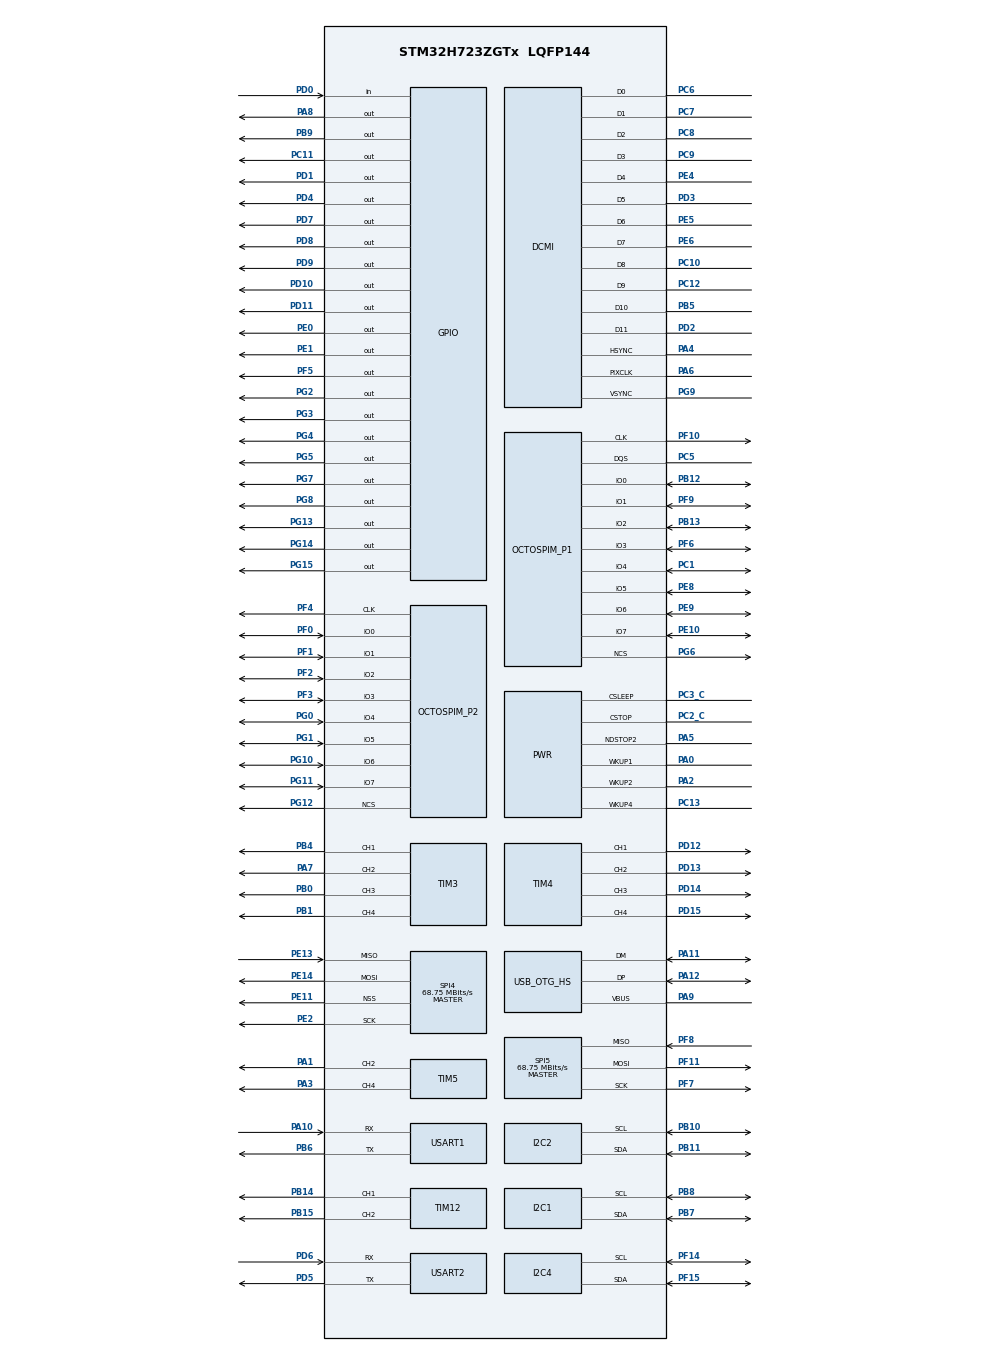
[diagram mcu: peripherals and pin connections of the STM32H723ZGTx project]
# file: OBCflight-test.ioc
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I2C1.Timing=0x60404E72
I2C2.Timing=0x60404E72
I2C4.Timing=0x60404E72
Mcu.Family=STM32H7
Mcu.Name=STM32H723ZGTx
Mcu.Package=LQFP144
NVIC.OTG_HS_IRQn=true\:0\:0\:false\:false\:true\:false\:true\:true
NVIC.PriorityGroup=NVIC_PRIORITYGROUP_4
NVIC.TIM2_IRQn=true\:15\:0\:false\:false\:true\:false\:true\:true
NVIC.TimeBase=TIM2_IRQn
NVIC.TimeBaseIP=TIM2
OCTOSPI1.ChipSelectBoundary=10
OCTOSPI1.ClockPrescaler=4
OCTOSPI1.DelayBlockBypass=HAL_OSPI_DELAY_BLOCK_USED
OCTOSPI1.DelayHoldQuarterCycle=HAL_OSPI_DHQC_ENABLE
OCTOSPI1.DeviceSize=28
OCTOSPI1.DeviceType=SPI_DEVICE_RAM
OCTOSPI1.MemoryType=HAL_OSPI_MEMTYPE_APMEMORY
OCTOSPI1.Refresh=241
OCTOSPI2.ClockPrescaler=4
PA0.Mode=WakeUp1
PA0.Signal=PWR_WKUP1
PA1.Signal=S_TIM5_CH2
PA10.Mode=Asynchronous
PA10.Signal=USART1_RX
PA11.Mode=Device_Only_FS
PA11.Signal=USB_OTG_HS_DM
PA12.Mode=Device_Only_FS
PA12.Signal=USB_OTG_HS_DP
PA13(JTMS/SWDIO).Mode=JTAG_4_pins
PA13(JTMS/SWDIO).Signal=DEBUG_JTMS-SWDIO
PA14(JTCK/SWCLK).Mode=JTAG_4_pins
PA14(JTCK/SWCLK).Signal=DEBUG_JTCK-SWCLK
PA15(JTDI).Mode=JTAG_4_pins
PA15(JTDI).Signal=DEBUG_JTDI
PA2.Mode=WakeUp2
PA2.Signal=PWR_WKUP2
PA3.Signal=S_TIM5_CH4
PA4.Mode=Slave_12_bits_External_Synchro
PA4.Signal=DCMI_HSYNC
PA5.Mode=MonitoringState
PA5.Signal=PWR_NDSTOP2
PA6.Mode=Slave_12_bits_External_Synchro
PA6.Signal=DCMI_PIXCLK
PA7.Signal=S_TIM3_CH2
PA8.Signal=GPIO_Output
PA9.Mode=Activate_VBUS_FS
PA9.Signal=USB_OTG_HS_VBUS
PB0.Signal=S_TIM3_CH3
PB1.Signal=S_TIM3_CH4
PB10.Mode=I2C
PB10.Signal=I2C2_SCL
PB11.Mode=I2C
PB11.Signal=I2C2_SDA
PB12.Mode=OCTOSPI1_IOL_Port1L
PB12.Signal=OCTOSPIM_P1_IO0
PB13.Mode=OCTOSPI1_IOL_Port1L
PB13.Signal=OCTOSPIM_P1_IO2
PB14.Signal=S_TIM12_CH1
PB15.Signal=S_TIM12_CH2
PB3(JTDO/TRACESWO).Mode=JTAG_4_pins
PB3(JTDO/TRACESWO).Signal=DEBUG_JTDO-SWO
PB4(NJTRST).Signal=S_TIM3_CH1
PB5.Mode=Slave_12_bits_External_Synchro
PB5.Signal=DCMI_D10
PB6.Mode=Asynchronous
PB6.Signal=USART1_TX
PB7.Mode=I2C
PB7.Signal=I2C1_SDA
PB8.Mode=I2C
PB8.Signal=I2C1_SCL
PB9.Signal=GPIO_Output
PC1.Mode=OCTOSPI1_IOH_Port1H
PC1.Signal=OCTOSPIM_P1_IO4
PC10.Mode=Slave_12_bits_External_Synchro
PC10.Signal=DCMI_D8
PC11.Signal=GPIO_Output
PC12.Mode=Slave_12_bits_External_Synchro
PC12.Signal=DCMI_D9
PC13.Mode=WakeUp4
PC13.Signal=PWR_WKUP4
PC14-OSC32_IN.Mode=LSE-External-Oscillator
PC14-OSC32_IN.Signal=RCC_OSC32_IN
PC15-OSC32_OUT.Mode=LSE-External-Oscillator
PC15-OSC32_OUT.Signal=RCC_OSC32_OUT
PC2_C.Mode=MonitoringState
PC2_C.Signal=PWR_CSTOP
PC3_C.Mode=MonitoringState
PC3_C.Signal=PWR_CSLEEP
PC5.Mode=OCTOSPI1_Port1_DQS
PC5.Signal=OCTOSPIM_P1_DQS
PC6.Mode=Slave_12_bits_External_Synchro
PC6.Signal=DCMI_D0
PC7.Mode=Slave_12_bits_External_Synchro
PC7.Signal=DCMI_D1
PC8.Mode=Slave_12_bits_External_Synchro
PC8.Signal=DCMI_D2
PC9.Mode=Slave_12_bits_External_Synchro
PC9.Signal=DCMI_D3
PD0.Signal=GPIO_Input
PD1.Signal=GPIO_Output
PD10.Signal=GPIO_Output
PD11.Signal=GPIO_Output
PD12.Signal=S_TIM4_CH1
PD13.Signal=S_TIM4_CH2
PD14.Signal=S_TIM4_CH3
PD15.Signal=S_TIM4_CH4
PD2.Mode=Slave_12_bits_External_Synchro
PD2.Signal=DCMI_D11
PD3.Mode=Slave_12_bits_External_Synchro
PD3.Signal=DCMI_D5
PD4.Signal=GPIO_Output
PD5.Mode=Asynchronous
PD5.Signal=USART2_TX
PD6.Mode=Asynchronous
PD6.Signal=USART2_RX
PD7.Signal=GPIO_Output
PD8.Signal=GPIO_Output
PD9.Signal=GPIO_Output
PE0.Signal=GPIO_Output
PE1.Signal=GPIO_Output
PE10.Mode=OCTOSPI1_IOH_Port1H
PE10.Signal=OCTOSPIM_P1_IO7
PE11.Mode=NSS_Signal_Hard_Output
PE11.Signal=SPI4_NSS
PE13.Mode=Full_Duplex_Master
PE13.Signal=SPI4_MISO
PE14.Mode=Full_Duplex_Master
PE14.Signal=SPI4_MOSI
PE2.Mode=Full_Duplex_Master
PE2.Signal=SPI4_SCK
PE4.Mode=Slave_12_bits_External_Synchro
PE4.Signal=DCMI_D4
PE5.Mode=Slave_12_bits_External_Synchro
PE5.Signal=DCMI_D6
PE6.Mode=Slave_12_bits_External_Synchro
PE6.Signal=DCMI_D7
PE8.Mode=OCTOSPI1_IOH_Port1H
PE8.Signal=OCTOSPIM_P1_IO5
PE9.Mode=OCTOSPI1_IOH_Port1H
PE9.Signal=OCTOSPIM_P1_IO6
PF0.Mode=OCTOSPI2_IOL_Port2L
PF0.Signal=OCTOSPIM_P2_IO0
PF1.Mode=OCTOSPI2_IOL_Port2L
PF1.Signal=OCTOSPIM_P2_IO1
PF10.Mode=O1_P1_CLK
PF10.Signal=OCTOSPIM_P1_CLK
PF11.Mode=Full_Duplex_Master
PF11.Signal=SPI5_MOSI
PF14.Mode=I2C
PF14.Signal=I2C4_SCL
PF15.Mode=I2C
PF15.Signal=I2C4_SDA
PF2.Mode=OCTOSPI2_IOL_Port2L
PF2.Signal=OCTOSPIM_P2_IO2
PF3.Mode=OCTOSPI2_IOL_Port2L
PF3.Signal=OCTOSPIM_P2_IO3
PF4.Mode=O2_P2_CLK
PF4.Signal=OCTOSPIM_P2_CLK
PF5.Signal=GPIO_Output
PF6.Mode=OCTOSPI1_IOL_Port1L
PF6.Signal=OCTOSPIM_P1_IO3
PF7.Mode=Full_Duplex_Master
PF7.Signal=SPI5_SCK
PF8.Mode=Full_Duplex_Master
PF8.Signal=SPI5_MISO
PF9.Mode=OCTOSPI1_IOL_Port1L
PF9.Signal=OCTOSPIM_P1_IO1
PG0.Mode=OCTOSPI2_IOH_Port2H
PG0.Signal=OCTOSPIM_P2_IO4
PG1.Mode=OCTOSPI2_IOH_Port2H
PG1.Signal=OCTOSPIM_P2_IO5
PG10.Mode=OCTOSPI2_IOH_Port2H
PG10.Signal=OCTOSPIM_P2_IO6
PG11.Mode=OCTOSPI2_IOH_Port2H
PG11.Signal=OCTOSPIM_P2_IO7
PG12.Mode=OCTOSPI2_Port2_NCS
PG12.Signal=OCTOSPIM_P2_NCS
PG13.Signal=GPIO_Output
PG14.Signal=GPIO_Output
PG15.Signal=GPIO_Output
PG2.Signal=GPIO_Output
PG3.Signal=GPIO_Output
PG4.Signal=GPIO_Output
PG5.GPIO_PuPd=GPIO_PULLUP
PG5.PinState=GPIO_PIN_SET
PG5.Signal=GPIO_Output
PG6.Mode=OCTOSPI1_Port1_NCS
PG6.Signal=OCTOSPIM_P1_NCS
PG7.Signal=GPIO_Output
PG8.Signal=GPIO_Output
PG9.Mode=Slave_12_bits_External_Synchro
PG9.Signal=DCMI_VSYNC
PH0-OSC_IN.Mode=HSE-External-Oscillator
PH0-OSC_IN.Signal=RCC_OSC_IN
PH1-OSC_OUT.Mode=HSE-External-Oscillator
PH1-OSC_OUT.Signal=RCC_OSC_OUT
ProjectManager.HeapSize=0x200
ProjectManager.StackSize=0x400
ProjectManager.TargetToolchain=STM32CubeIDE
RAMECC.Instance-RAMECC1_Monitor1=RAMECC1_Monitor1
RAMECC.Instance-RAMECC1_Monitor2=RAMECC1_Monitor2
RAMECC.Instance-RAMECC1_Monitor3=RAMECC1_Monitor3
RAMECC.Instance-RAMECC1_Monitor4=RAMECC1_Monitor4
RAMECC.Instance-RAMECC1_Monitor5=RAMECC1_Monitor5
RAMECC.Instance-RAMECC1_Monitor6=RAMECC1_Monitor6
RAMECC.Instance-RAMECC2_Monitor1=RAMECC2_Monitor1
RAMECC.Instance-RAMECC2_Monitor2_1=RAMECC2_Monitor2
RAMECC.Instance-RAMECC2_Monitor3_1=RAMECC2_Monitor3
RAMECC.Instance-RAMECC3_Monitor1=RAMECC3_Monitor1
RAMECC.Instance-RAMECC3_Monitor2=RAMECC3_Monitor2
RCC.ADCFreq_Value=129000000
RCC.APB1Freq_Value=137500000
RCC.APB2Freq_Value=137500000
RCC.APB3Freq_Value=137500000
RCC.APB4Freq_Value=137500000
RCC.CortexFreq_Value=550000000
RCC.D1PPRE=RCC_APB3_DIV2
RCC.D2PPRE1=RCC_APB1_DIV2
RCC.D2PPRE2=RCC_APB2_DIV2
RCC.D3PPRE=RCC_APB4_DIV2
RCC.DIVM1=4
RCC.DIVN1=34
RCC.DIVP1=1
RCC.DIVQ1=5
RCC.HCLKFreq_Value=275000000
RCC.HPRE=RCC_HCLK_DIV2
RCC.HSE_VALUE=48000000
RCC.PLL2FRACN=0
RCC.PLL3FRACN=0
RCC.PLLFRACN=3072
RCC.SYSCLKFreq_VALUE=550000000
RCC.SYSCLKSource=RCC_SYSCLKSOURCE_PLLCLK
RCC.USBCLockSelection=RCC_USBCLKSOURCE_HSI48
RCC.USBFreq_Value=48000000
SH.S_TIM12_CH1.0=TIM12_CH1,PWM Generation1 CH1
SH.S_TIM12_CH2.0=TIM12_CH2,PWM Generation2 CH2
SH.S_TIM3_CH1.0=TIM3_CH1,PWM Generation1 CH1
SH.S_TIM3_CH2.0=TIM3_CH2,PWM Generation2 CH2
SH.S_TIM3_CH3.0=TIM3_CH3,PWM Generation3 CH3
SH.S_TIM3_CH4.0=TIM3_CH4,PWM Generation4 CH4
SH.S_TIM4_CH1.0=TIM4_CH1,PWM Generation1 CH1
SH.S_TIM4_CH2.0=TIM4_CH2,PWM Generation2 CH2
SH.S_TIM4_CH3.0=TIM4_CH3,PWM Generation3 CH3
SH.S_TIM4_CH4.0=TIM4_CH4,PWM Generation4 CH4
SH.S_TIM5_CH2.0=TIM5_CH2,PWM Generation2 CH2
SH.S_TIM5_CH4.0=TIM5_CH4,PWM Generation4 CH4
SPI4.CalculateBaudRate=68.75 MBits/s
SPI4.Direction=SPI_DIRECTION_2LINES
SPI4.Mode=SPI_MODE_MASTER
SPI4.VirtualNSS=VM_NSSHARD
SPI4.VirtualType=VM_MASTER
SPI5.CalculateBaudRate=68.75 MBits/s
SPI5.Direction=SPI_DIRECTION_2LINES
SPI5.Mode=SPI_MODE_MASTER
SPI5.VirtualType=VM_MASTER
TIM12.Channel-PWM\ Generation1\ CH1=TIM_CHANNEL_1
TIM12.Channel-PWM\ Generation2\ CH2=TIM_CHANNEL_2
TIM3.Channel-PWM\ Generation1\ CH1=TIM_CHANNEL_1
TIM3.Channel-PWM\ Generation2\ CH2=TIM_CHANNEL_2
TIM3.Channel-PWM\ Generation3\ CH3=TIM_CHANNEL_3
TIM3.Channel-PWM\ Generation4\ CH4=TIM_CHANNEL_4
TIM4.Channel-PWM\ Generation1\ CH1=TIM_CHANNEL_1
TIM4.Channel-PWM\ Generation2\ CH2=TIM_CHANNEL_2
TIM4.Channel-PWM\ Generation3\ CH3=TIM_CHANNEL_3
TIM4.Channel-PWM\ Generation4\ CH4=TIM_CHANNEL_4
TIM5.Channel-PWM\ Generation2\ CH2=TIM_CHANNEL_2
TIM5.Channel-PWM\ Generation4\ CH4=TIM_CHANNEL_4
USART1.VirtualMode-Asynchronous=VM_ASYNC
USART2.VirtualMode-Asynchronous=VM_ASYNC
USB_DEVICE.CLASS_NAME_HS=MSC
USB_DEVICE.PRODUCT_STRING_MSC_HS=PicoSat Storage
USB_DEVICE.VirtualMode=Msc
USB_DEVICE.VirtualModeHS=Msc_HS
USB_OTG_HS.VirtualMode-Device_Only_FS=Device_Only_FS
VP_CRC_VS_CRC.Mode=CRC_Activate
VP_FATFS_VS_Generic.Mode=User_defined
VP_OCTOSPI1_VS_octo.Mode=octo_mode
VP_OCTOSPI2_VS_octo.Mode=dual_quad_mode
VP_RAMECC_VS_D1_1.Mode=RAMECC1_Monitor1
VP_RAMECC_VS_D1_2.Mode=RAMECC1_Monitor2
VP_RAMECC_VS_D1_3.Mode=RAMECC1_Monitor3
VP_RAMECC_VS_D1_4.Mode=RAMECC1_Monitor4
VP_RAMECC_VS_D1_5.Mode=RAMECC1_Monitor5
VP_RAMECC_VS_D1_6.Mode=RAMECC1_Monitor6
VP_RAMECC_VS_D2_1.Mode=RAMECC2_Monitor1
VP_RAMECC_VS_D2_2.Mode=RAMECC2_Monitor2_1
VP_RAMECC_VS_D2_3.Mode=RAMECC2_Monitor3_1
VP_RAMECC_VS_D3_1.Mode=RAMECC3_Monitor1
VP_RAMECC_VS_D3_2.Mode=RAMECC3_Monitor2
VP_RCC_LSE.Mode=CRS SYNC Source LSE
VP_RNG_VS_RNG.Mode=RNG_Activate
VP_RTC_VS_RTC_Activate.Mode=RTC_Enabled
VP_RTC_VS_RTC_Calendar.Mode=RTC_Calendar
VP_RTC_VS_RTC_WakeUp_intern.Mode=WakeUp
VP_SYS_VS_tim2.Mode=TIM2
VP_TIM3_VS_ClockSourceINT.Mode=Internal
VP_TIM4_VS_ClockSourceINT.Mode=Internal
VP_TIM5_VS_ClockSourceINT.Mode=Internal
VP_USB_DEVICE_VS_USB_DEVICE_MSC_HS.Mode=MSC_HS
board=custom

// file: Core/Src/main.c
/* USER CODE BEGIN Header */
/**
  ******************************************************************************
  * @file           : main.c
  * @brief          : Main program body
  ******************************************************************************
  * @attention
  *
  * Copyright (c) 2023 STMicroelectronics.
  * All rights reserved.
  *
  * This software is licensed under terms that can be found in the LICENSE file
  * in the root directory of this software component.
  * If no LICENSE file comes with this software, it is provided AS-IS.
  *
  ******************************************************************************
  */
/* USER CODE END Header */
#include "main.h"
#include "crc.h"
#include "dcmi.h"
#include "fatfs.h"
#include "i2c.h"
#include "octospi.h"
#include "ramecc.h"
#include "rng.h"
#include "rtc.h"
#include "spi.h"
#include "tim.h"
#include "usart.h"
#include "usb_device.h"
#include "gpio.h"

/* USER CODE BEGIN Includes */
#include "log.h"
#include "TMP117.h"
#include "aps6408.h"
#include "aps6408_conf.h"
#include "W25Nxx.h"
#include "stm32l4p5g_discovery_psram.h"
#define CONFIG_YAFFS_DIRECT 1
#include "yaffs_yaffs2.h"
/* USER CODE END Includes */

/* USER CODE BEGIN PTD */
#define BUFFERSIZE (COUNTOF(aTxBuffer) - 1)
#define COUNTOF(__BUFFER__) (sizeof(__BUFFER__) / sizeof(*(__BUFFER__)))
#define DLYB_BUFFERSIZE (COUNTOF(Cal_buffer) - 1)
#define EXTENDEDBUFFERSIZE (1048576)
/* USER CODE END PTD */

/* USER CODE BEGIN PV */
uint8_t aTxBuffer[] = " **OCTOSPI/Octal-spi PSRAM Memory-mapped communication example** **OCTOSPI/Octal-spi PSRAM Memory-mapped communication example** **OCTOSPI/Octal-spi PSRAM Memory-mapped communication example** **OCTOSPI/Octal-spi PSRAM Memory-mapped communication example**";
uint8_t aRxBuffer[512];

static char * testString = "This is a test string, for testing memory.";
static char recvString[128];
/* USER CODE END PV */

void SystemClock_Config(void);
/* USER CODE BEGIN PFP */
static void test_PSRAM(void);
static void test_NAND(void);
/* USER CODE END PFP */

/* USER CODE BEGIN 0 */
TMP117_dev temp_A;
W25Nxx_dev W25N;
/* USER CODE END 0 */

int main(void)
{

  /* MCU Configuration--------------------------------------------------------*/

  /* Reset of all peripherals, Initializes the Flash interface and the Systick. */
  HAL_Init();

  /* Configure the system clock */
  SystemClock_Config();

  /* Initialize all configured peripherals */
  MX_GPIO_Init();
  MX_DCMI_Init();
  MX_I2C1_Init();
  MX_I2C2_Init();
  MX_OCTOSPI1_Init();
  MX_USART1_UART_Init();
  MX_I2C4_Init();
  MX_OCTOSPI2_Init();
  MX_RAMECC_Init();
  MX_USART2_UART_Init();
  MX_SPI4_Init();
  MX_CRC_Init();
  MX_RNG_Init();
  MX_RTC_Init();
  MX_TIM3_Init();
  MX_TIM4_Init();
  MX_TIM12_Init();
  MX_SPI5_Init();
  MX_TIM5_Init();
  MX_FATFS_Init();
  MX_USB_DEVICE_Init();
  /* USER CODE BEGIN 2 */
  log_info("Main Init");
  test_NAND();
  test_PSRAM();

  /*
  if (BSP_PSRAM_Init() != PSRAM_OK) {
	  log_error("APS12808 error");
  }
  BSP_PSRAM_WriteData(0x00, (uint8_t *) testString, 43);
  BSP_PSRAM_ReadData(0x00, (uint8_t *) recvString, 43);

  BSP_PSRAM_EnableMemoryMappedMode();
   */

  /* USER CODE END 2 */

  /* Infinite loop */
  while (1)
  {

  }
}

void SystemClock_Config(void)
{
  RCC_OscInitTypeDef RCC_OscInitStruct = {0};
  RCC_ClkInitTypeDef RCC_ClkInitStruct = {0};
  RCC_CRSInitTypeDef RCC_CRSInitStruct = {0};

  /** Supply configuration update enable
  */
  HAL_PWREx_ConfigSupply(PWR_LDO_SUPPLY);

  /** Configure the main internal regulator output voltage
  */
  __HAL_PWR_VOLTAGESCALING_CONFIG(PWR_REGULATOR_VOLTAGE_SCALE0);

  while(!__HAL_PWR_GET_FLAG(PWR_FLAG_VOSRDY)) {}

  /** Configure LSE Drive Capability
  */
  HAL_PWR_EnableBkUpAccess();
  __HAL_RCC_LSEDRIVE_CONFIG(RCC_LSEDRIVE_LOW);

  /** Initializes the RCC Oscillators according to the specified parameters
  * in the RCC_OscInitTypeDef structure.
  */
  RCC_OscInitStruct.OscillatorType = RCC_OSCILLATORTYPE_HSI48|RCC_OSCILLATORTYPE_HSI
                              |RCC_OSCILLATORTYPE_LSI|RCC_OSCILLATORTYPE_LSE;
  RCC_OscInitStruct.LSEState = RCC_LSE_ON;
  RCC_OscInitStruct.HSIState = RCC_HSI_DIV1;
  RCC_OscInitStruct.HSICalibrationValue = 64;
  RCC_OscInitStruct.LSIState = RCC_LSI_ON;
  RCC_OscInitStruct.HSI48State = RCC_HSI48_ON;
  RCC_OscInitStruct.PLL.PLLState = RCC_PLL_ON;
  RCC_OscInitStruct.PLL.PLLSource = RCC_PLLSOURCE_HSI;
  RCC_OscInitStruct.PLL.PLLM = 4;
  RCC_OscInitStruct.PLL.PLLN = 34;
  RCC_OscInitStruct.PLL.PLLP = 1;
  RCC_OscInitStruct.PLL.PLLQ = 5;
  RCC_OscInitStruct.PLL.PLLR = 2;
  RCC_OscInitStruct.PLL.PLLRGE = RCC_PLL1VCIRANGE_3;
  RCC_OscInitStruct.PLL.PLLVCOSEL = RCC_PLL1VCOWIDE;
  RCC_OscInitStruct.PLL.PLLFRACN = 3072;
  if (HAL_RCC_OscConfig(&RCC_OscInitStruct) != HAL_OK)
  {
    Error_Handler();
  }

  /** Initializes the CPU, AHB and APB buses clocks
  */
  RCC_ClkInitStruct.ClockType = RCC_CLOCKTYPE_HCLK|RCC_CLOCKTYPE_SYSCLK
                              |RCC_CLOCKTYPE_PCLK1|RCC_CLOCKTYPE_PCLK2
                              |RCC_CLOCKTYPE_D3PCLK1|RCC_CLOCKTYPE_D1PCLK1;
  RCC_ClkInitStruct.SYSCLKSource = RCC_SYSCLKSOURCE_PLLCLK;
  RCC_ClkInitStruct.SYSCLKDivider = RCC_SYSCLK_DIV1;
  RCC_ClkInitStruct.AHBCLKDivider = RCC_HCLK_DIV2;
  RCC_ClkInitStruct.APB3CLKDivider = RCC_APB3_DIV2;
  RCC_ClkInitStruct.APB1CLKDivider = RCC_APB1_DIV2;
  RCC_ClkInitStruct.APB2CLKDivider = RCC_APB2_DIV2;
  RCC_ClkInitStruct.APB4CLKDivider = RCC_APB4_DIV2;

  if (HAL_RCC_ClockConfig(&RCC_ClkInitStruct, FLASH_LATENCY_3) != HAL_OK)
  {
    Error_Handler();
  }

  /** Enable the SYSCFG APB clock
  */
  __HAL_RCC_CRS_CLK_ENABLE();

  /** Configures CRS
  */
  RCC_CRSInitStruct.Prescaler = RCC_CRS_SYNC_DIV1;
  RCC_CRSInitStruct.Source = RCC_CRS_SYNC_SOURCE_LSE;
  RCC_CRSInitStruct.Polarity = RCC_CRS_SYNC_POLARITY_RISING;
  RCC_CRSInitStruct.ReloadValue = __HAL_RCC_CRS_RELOADVALUE_CALCULATE(48000000,32768);
  RCC_CRSInitStruct.ErrorLimitValue = 34;
  RCC_CRSInitStruct.HSI48CalibrationValue = 32;

  HAL_RCCEx_CRSConfig(&RCC_CRSInitStruct);
}

/* USER CODE BEGIN 4 */
static void test_NAND(void)
{
	W25N_setup(&W25N, &hospi2, 0);

	uint64_t nand_id = 0;
	uint16_t statReg = 0;
	if (W25N_ReadJEDECID(&W25N, &nand_id) == W25N_OK) {
	  log_info("W25N ID: %X", nand_id);
	}
	else {
	  log_error("Unable to read from W25N");
	}
	W25N_Write_Enable(&W25N);

	W25N_Read_Status_Reg(&W25N, W25N_STATUS_REG, &statReg);
	log_info("W25N status: %X", statReg);
	W25N_Read_Status_Reg(&W25N, W25N_CONFIG_REG, &statReg);
	log_info("W25N config: %X", statReg);
	W25N_Read_Status_Reg(&W25N, W25N_PROTECTION_REG, &statReg);
	log_info("W25N protection: %X", statReg);
	W25N_Write_Status_Reg(&W25N, W25N_PROTECTION_REG, 0x00); //Disable memory protection
	W25N_Write_Status_Reg(&W25N, W25N_CONFIG_REG, 0x18); //Enable ECC and buffer

	W25N_Block_Erase(&W25N, 0x0026);
	W25N_Read_Status_Reg(&W25N, W25N_STATUS_REG, &statReg);
	log_info("W25N status: %X", statReg);
	W25N_Read_Status_Reg(&W25N, W25N_PROTECTION_REG, &statReg);
	log_info("W25N protection: %X", statReg);
	W25N_Wait_Until_Not_Busy(&W25N, 30000);

	memset(aRxBuffer, 0xff, 512);

	W25N_Write_Enable(&W25N); //Must be called before Data load

	if (W25N_Load_Data_Quad(&W25N, 0x00, aTxBuffer, 256) != W25N_OK) {
	  log_error("W25N Unable to load data");
	}

	W25N_Program_Execute(&W25N, 0x0026);
	W25N_Read_Status_Reg(&W25N, W25N_STATUS_REG, &statReg);
	log_info("W25N status after execute: %X", statReg);
	W25N_Wait_Until_Not_Busy(&W25N, 30000);

	W25N_Read_Status_Reg(&W25N, W25N_STATUS_REG, &statReg);
	log_info("W25N status after execute done: %X", statReg);
	W25N_Page_Data_Read(&W25N, 0x0026);
	W25N_Read_Status_Reg(&W25N, W25N_STATUS_REG, &statReg);
	log_info("W25N status after page load: %X", statReg);
	W25N_Wait_Until_Not_Busy(&W25N, 30000);

	W25N_Read_Status_Reg(&W25N, W25N_STATUS_REG, &statReg);
	log_info("W25N status after page load done: %X", statReg);
	if (W25N_Read_Output_Quad(&W25N, 0x00, aRxBuffer, 256) != W25N_OK) {
	  log_error("W25N unable to read output");
	}

	if (aRxBuffer[0] == aTxBuffer[0]) {
	  log_info("----W25N R/W Success----");
	}
	else {
	  log_error("W25N R/W Failure");
	}
}

static void test_PSRAM(void)
{
	uint16_t id;
	if (APS6408_ReadID(&hospi1, &id, 5) != APS6408_OK) {
	  log_error("APS12808 error");
	}
	else {
	  log_info("APS12808 config: %X", id);
	}

	if (APS6408_Write(&hospi1, aTxBuffer, 0x00, 4, DUMMY_CLOCK_CYCLES_WRITE, APS6408_MR8_BL_32_BYTES) != HAL_OK) {
	  log_error("Unable to write to APS6408");
	}
	uint32_t testData = 0;
	if (APS6408_Read(&hospi1, (uint8_t *)&testData, 0x00, 4, DUMMY_CLOCK_CYCLES_READ, APS6408_MR8_BL_32_BYTES) != HAL_OK) {
	  log_error("Unable to write to APS6408");
	}

	if (testData != *((uint32_t *)aTxBuffer)) {
	  log_error("APS6048 Read/Write Fail");
	}
	else {
	  log_info("APS6048 Read/Write Success");
	}

	if (APS6408_EnableMemoryMappedMode(&hospi1, 5, DUMMY_CLOCK_CYCLES_WRITE, APS6408_MR8_BL_32_BYTES) != HAL_OK)
	{
	  log_error("Unable to start APS6408 memory mapped mode");
	}

	__IO uint8_t *mem_addr;
	uint32_t address = 0;
	uint16_t index1;/*index1 counter of bytes used when reading/writing 256 bytes buffer */
	uint16_t index2;/*index2 counter of 256 bytes buffer used */
	bool noErrors = true;
	mem_addr = (__IO uint8_t *)(OCTOSPI1_BASE + address);
	//Writing 1Mbyte (256Byte BUFFERSIZE x 4096 times)
	for (index2 = 0; index2 < EXTENDEDBUFFERSIZE/BUFFERSIZE; index2++)
	{
		for (index1 = 0; index1 < BUFFERSIZE; index1++)
		{
			*mem_addr = aTxBuffer[index1];
			mem_addr++;
		}
	}
	//----------------------------------------------------------------------
	//Reading Sequence of 1Mbyte
	mem_addr = (__IO uint8_t *)(OCTOSPI1_BASE + address);
	//Reading 1Mbyte (256Byte BUFFERSIZE x 4096 times)
	for (index2 = 0; index2 < EXTENDEDBUFFERSIZE/BUFFERSIZE; index2++) {
		for (index1 = 0; index1 < BUFFERSIZE; index1++)
		{
			uint8_t data = *mem_addr;
			if (data != aTxBuffer[index1])
			{
				//if data read is corrupted we can toggle a led here: example blue led
				//log_error("Data Corrupt, %d != %d", data, aTxBuffer[index1]);
				noErrors = false;
			}
				mem_addr++;
		}
	}

	if (noErrors) {
		log_info("PSRAM data transfer success");
	}
	else {
		log_info("PSRAM data transfer failure");
	}
}

/* USER CODE END 4 */

void HAL_TIM_PeriodElapsedCallback(TIM_HandleTypeDef *htim)
{
  if (htim->Instance == TIM2) {
    HAL_IncTick();
  }
}

void Error_Handler(void)
{
  __disable_irq();
  while (1)
  {
  }
}
